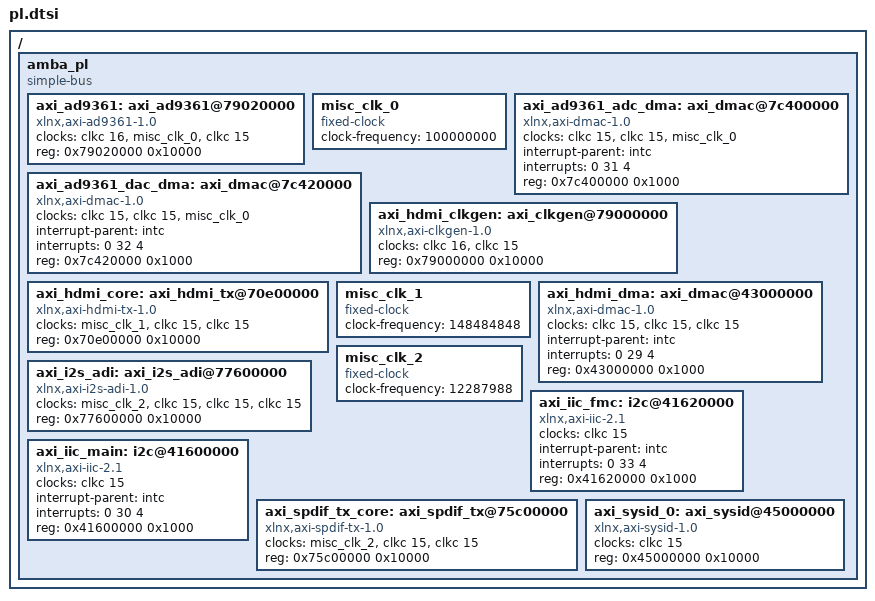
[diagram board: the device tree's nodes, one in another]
/*
 * CAUTION: This file is automatically generated by Xilinx.
 * Version:  
 * Today is: Fri Sep 15 15:03:11 2023
 */


/ {
	amba_pl: amba_pl {
		#address-cells = <1>;
		#size-cells = <1>;
		compatible = "simple-bus";
		ranges ;
		axi_ad9361: axi_ad9361@79020000 {
			clock-names = "delay_clk", "clk", "s_axi_aclk";
			clocks = <&clkc 16>, <&misc_clk_0>, <&clkc 15>;
			compatible = "xlnx,axi-ad9361-1.0";
			reg = <0x79020000 0x10000>;
		};
		misc_clk_0: misc_clk_0 {
			#clock-cells = <0>;
			clock-frequency = <100000000>;
			compatible = "fixed-clock";
		};
		axi_ad9361_adc_dma: axi_dmac@7c400000 {
			clock-names = "s_axi_aclk", "m_dest_axi_aclk", "fifo_wr_clk";
			clocks = <&clkc 15>, <&clkc 15>, <&misc_clk_0>;
			compatible = "xlnx,axi-dmac-1.0";
			interrupt-names = "irq";
			interrupt-parent = <&intc>;
			interrupts = <0 31 4>;
			reg = <0x7c400000 0x1000>;
		};
		axi_ad9361_dac_dma: axi_dmac@7c420000 {
			clock-names = "s_axi_aclk", "m_src_axi_aclk", "m_axis_aclk";
			clocks = <&clkc 15>, <&clkc 15>, <&misc_clk_0>;
			compatible = "xlnx,axi-dmac-1.0";
			interrupt-names = "irq";
			interrupt-parent = <&intc>;
			interrupts = <0 32 4>;
			reg = <0x7c420000 0x1000>;
		};
		axi_hdmi_clkgen: axi_clkgen@79000000 {
			clock-names = "clk", "s_axi_aclk";
			clocks = <&clkc 16>, <&clkc 15>;
			compatible = "xlnx,axi-clkgen-1.0";
			reg = <0x79000000 0x10000>;
		};
		axi_hdmi_core: axi_hdmi_tx@70e00000 {
			clock-names = "reference_clk", "vdma_clk", "s_axi_aclk";
			clocks = <&misc_clk_1>, <&clkc 15>, <&clkc 15>;
			compatible = "xlnx,axi-hdmi-tx-1.0";
			reg = <0x70e00000 0x10000>;
		};
		misc_clk_1: misc_clk_1 {
			#clock-cells = <0>;
			clock-frequency = <148484848>;
			compatible = "fixed-clock";
		};
		axi_hdmi_dma: axi_dmac@43000000 {
			clock-names = "s_axi_aclk", "m_src_axi_aclk", "m_axis_aclk";
			clocks = <&clkc 15>, <&clkc 15>, <&clkc 15>;
			compatible = "xlnx,axi-dmac-1.0";
			interrupt-names = "irq";
			interrupt-parent = <&intc>;
			interrupts = <0 29 4>;
			reg = <0x43000000 0x1000>;
		};
		axi_i2s_adi: axi_i2s_adi@77600000 {
			clock-names = "data_clk_i", "dma_req_tx_aclk", "dma_req_rx_aclk", "s_axi_aclk";
			clocks = <&misc_clk_2>, <&clkc 15>, <&clkc 15>, <&clkc 15>;
			compatible = "xlnx,axi-i2s-adi-1.0";
			reg = <0x77600000 0x10000>;
		};
		misc_clk_2: misc_clk_2 {
			#clock-cells = <0>;
			clock-frequency = <12287988>;
			compatible = "fixed-clock";
		};
		axi_iic_fmc: i2c@41620000 {
			#address-cells = <1>;
			#size-cells = <0>;
			clock-names = "s_axi_aclk";
			clocks = <&clkc 15>;
			compatible = "xlnx,axi-iic-2.1", "xlnx,xps-iic-2.00.a";
			interrupt-names = "iic2intc_irpt";
			interrupt-parent = <&intc>;
			interrupts = <0 33 4>;
			reg = <0x41620000 0x1000>;
		};
		axi_iic_main: i2c@41600000 {
			#address-cells = <1>;
			#size-cells = <0>;
			clock-names = "s_axi_aclk";
			clocks = <&clkc 15>;
			compatible = "xlnx,axi-iic-2.1", "xlnx,xps-iic-2.00.a";
			interrupt-names = "iic2intc_irpt";
			interrupt-parent = <&intc>;
			interrupts = <0 30 4>;
			reg = <0x41600000 0x1000>;
		};
		axi_spdif_tx_core: axi_spdif_tx@75c00000 {
			clock-names = "spdif_data_clk", "s_axi_aclk", "dma_req_aclk";
			clocks = <&misc_clk_2>, <&clkc 15>, <&clkc 15>;
			compatible = "xlnx,axi-spdif-tx-1.0";
			reg = <0x75c00000 0x10000>;
		};
		axi_sysid_0: axi_sysid@45000000 {
			clock-names = "s_axi_aclk";
			clocks = <&clkc 15>;
			compatible = "xlnx,axi-sysid-1.0";
			reg = <0x45000000 0x10000>;
		};
	};
};
